# STM32N655 register map
File version: 1.0
CPU: CM55 r0p1, little endian, no MPU, FPU, vendor SysTick, 8 interrupt priority bits
Registers are 32-bit, read-write, reset 0x0 unless marked. A register's access mark holds for its fields unless they carry their own. Offsets are from the block's base; [hi:lo] are bit positions; lines under a group give offsets from that group; {n}, {i} and the like mark numbered series; 'fields as' and 'values as' point back to an identical list.

## DCMIPP (part 2 of 2) — Digital camera interface pixel pipeline
Base 0x48002000
Same registers: DCMIPP_S 0x58002000
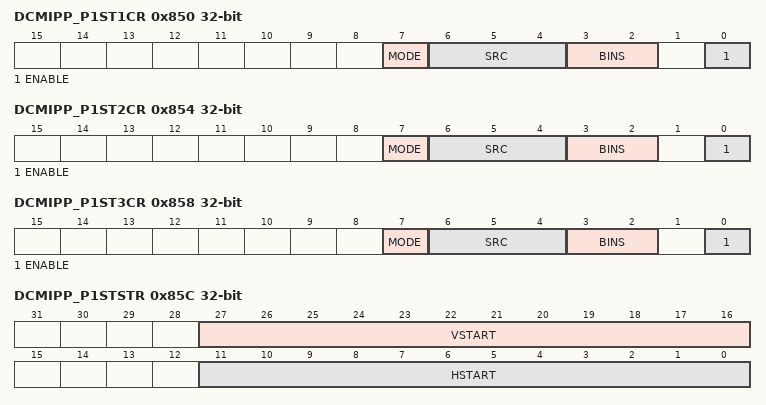
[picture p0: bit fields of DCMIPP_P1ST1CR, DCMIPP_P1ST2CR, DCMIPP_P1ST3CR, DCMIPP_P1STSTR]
0x850 DCMIPP_P1ST1CR — DCMIPP Pipe1 statistics1 control register
  [7] MODE — Statistics mode
    0=Average: accumulates the 8-bit component value of the considered pixel components; 1=Bins: accumulates 256 for each considered pixel component fitting a bin dynamic
  [6:4] SRC — Statistics source
  [3:2] BINS — Current bin definition
    0=All Pixels: Accu is incremented of Component, if 0 less than or equal to Component less than 256; 1=NoExt16: Accu is incremented of Component, if 16 less than or equal to Component less than 240
  [0] ENABLE
    0=Disabled: statistics are not accumulated; 1=Enable: statistics are accumulated
0x854 DCMIPP_P1ST2CR — DCMIPP Pipe1 statistics 2 control register
  [7] MODE — Statistics mode
    values as DCMIPP_P1ST1CR.MODE
  [6:4] SRC — Statistics source
  [3:2] BINS — Bin definition
    0=AllPixels: Accu is incremented of Component, if 0 less than or equal to Component less than 256; 1=NoExt16: Accu is incremented of Component, if 16 less than or equal to Component less than 240
  [0] ENABLE
    0=Disabled: statistics are not accumulated; 1=Enabled: statistics are accumulated
0x858 DCMIPP_P1ST3CR — DCMIPP Pipe1 statistics 3 control register
  fields as DCMIPP_P1ST2CR
0x85C DCMIPP_P1STSTR — DCMIPP Pipe1 statistics window start register
  [27:16] VSTART — Vertical start, from 0 to 4094 pixels high
  [11:0] HSTART — Horizontal start, from 0 to 4094 pixels wide
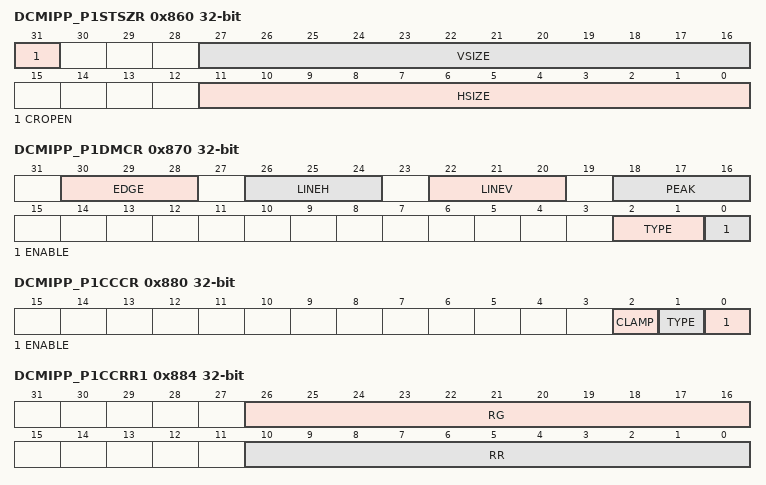
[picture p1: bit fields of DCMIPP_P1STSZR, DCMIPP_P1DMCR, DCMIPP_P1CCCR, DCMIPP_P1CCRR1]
0x860 DCMIPP_P1STSZR — DCMIPP Pipe1 statistics window size register
  [31] CROPEN
    0=Bypass, all pixels are used to compute the statistics; 1=Enable, only the rectangle defined by VSTART, HSTART, VSIZE, HSIZE is used for statistics
  [27:16] VSIZE — Vertical size, from 0 to 4094 pixels high
  [11:0] HSIZE — Horizontal size, from 0 to 4094 pixels wide
0x864 DCMIPP_P1ST1SR ro — DCMIPP Pipe1 statistics 1 status register
  [23:0] ACCU — Accumulation result, divided by 256.
0x868 DCMIPP_P1ST2SR ro — DCMIPP Pipe1 statistics 2 status register
  [23:0] ACCU — accumulation result, divided by 256.
0x86C DCMIPP_P1ST3SR ro — DCMIPP Pipe1 statistics 3 status register
  [23:0] ACCU — accumulation result, divided by 256.
0x870 DCMIPP_P1DMCR — DCMIPP Pipe1 demosaicing configuration register
  [30:28] EDGE — Strength of the edge detection
    0=No edge detection, pure linear interpolation
  [26:24] LINEH — Strength of the horizontal line detection
    0=No horizontal line detection, pure linear interpolation
  [22:20] LINEV — Strength of the vertical line detection
    0=No vertical line detection, pure linear interpolation
  [18:16] PEAK — Strength of the peak detection
    0=No peak detection, pure linear interpolation
  [2:1] TYPE — Raw Bayer type
    0=RGGB; 1=GRBG; 2=GBRG; 3=BGGR
  [0] ENABLE
    0=Bypass; 1=Enable demosaicing
0x880 DCMIPP_P1CCCR — DCMIPP Pipe1 ColorConv configuration register
  [2] CLAMP — Clamp the output samples
    0=Not activated (clamped to [0;255] by default); 1=Activated, depending on TYPE
  [1] TYPE — output samples type used while CLAMP is activated
    0=Clamped to [16;235] for Y and to [16;240] for U and V; 1=Clamped to [16;235] for R, G and B
  [0] ENABLE
    0=ColorConv is bypassed; 1=ColorConv is enabled
0x884 DCMIPP_P1CCRR1 — DCMIPP Pipe1 ColorConv red coefficient register 1
  [26:16] RG — Coefficient row 1 column 2 of the matrix
  [10:0] RR — Coefficient row 1 column 1 of the matrix
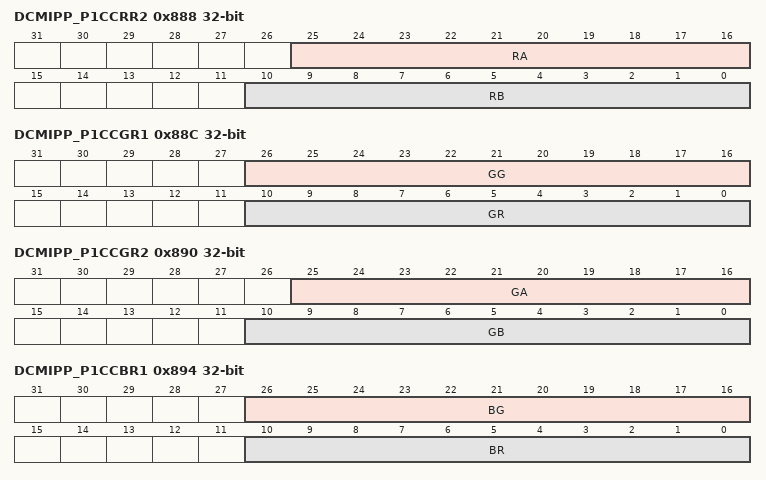
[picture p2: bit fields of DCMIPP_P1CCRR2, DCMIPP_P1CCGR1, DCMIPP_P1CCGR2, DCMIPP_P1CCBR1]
0x888 DCMIPP_P1CCRR2 — DCMIPP Pipe1 ColorConv red coefficient register 2
  [25:16] RA — Coefficient row 1 of the added column (signed integer value)
  [10:0] RB — Coefficient row 1 column 3 of the matrix
0x88C DCMIPP_P1CCGR1 — DCMIPP Pipe1 ColorConv green coefficient register 1
  [26:16] GG — Coefficient row 2 column 2 of the matrix
  [10:0] GR — Coefficient row 2 column 1 of the matrix
0x890 DCMIPP_P1CCGR2 — DCMIPP Pipe1 ColorConv green coefficient register 2
  [25:16] GA — Coefficient row 2 of the added column (signed integer value)
  [10:0] GB — Coefficient row 2 column 3 of the matrix
0x894 DCMIPP_P1CCBR1 — DCMIPP Pipex ColorConv blue coefficient register 1
  [26:16] BG — Coefficient row 3 column 2 of the matrix
  [10:0] BR — Coefficient row 3 column 1 of the matrix
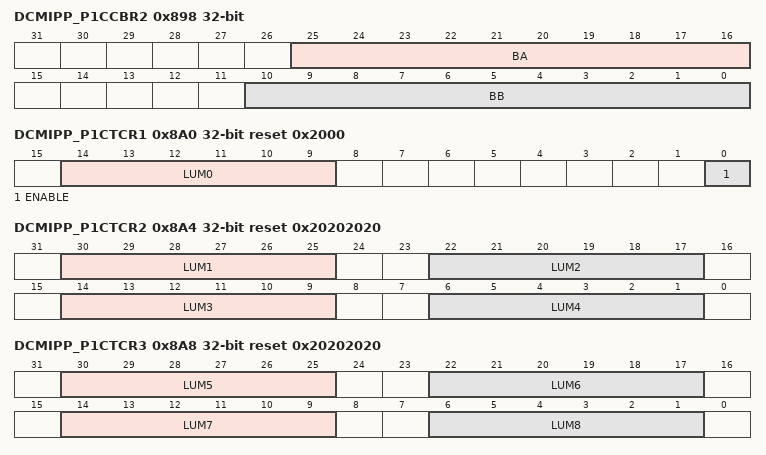
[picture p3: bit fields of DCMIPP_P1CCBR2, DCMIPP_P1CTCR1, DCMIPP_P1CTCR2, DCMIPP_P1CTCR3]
0x898 DCMIPP_P1CCBR2 — DCMIPP Pipe1 ColorConv blue coefficient register 2
  [25:16] BA — Coefficient row 3 of the added column (signed integer value)
  [10:0] BB — Coefficient row 3 column 3 of the matrix
0x8A0 DCMIPP_P1CTCR1 reset 0x2000 — DCMIPP Pipe1 contrast control register 1
  [14:9] LUM0 — Luminance increase for input luminance of 0 (increase is idle with LUMx = 16)
  [0] ENABLE
    0=Bypass, pixels are forwarded idle; 1=Enable, contrast enhancement is applied on pixels
0x8A4 DCMIPP_P1CTCR2 reset 0x20202020 — DCMIPP Pipe1 contrast control register 2
  [38-8n:33-8n] LUM{n} (n=1..4) — Luminance increase for input luminance of {32n} (increase is idle with LUMx = 16)
0x8A8 DCMIPP_P1CTCR3 reset 0x20202020 — DCMIPP Pipe1 contrast control register 3
  [70-8n:65-8n] LUM{n} (n=5..8) — Luminance increase for input luminance of {32n} (increase is idle with LUMx = 16)
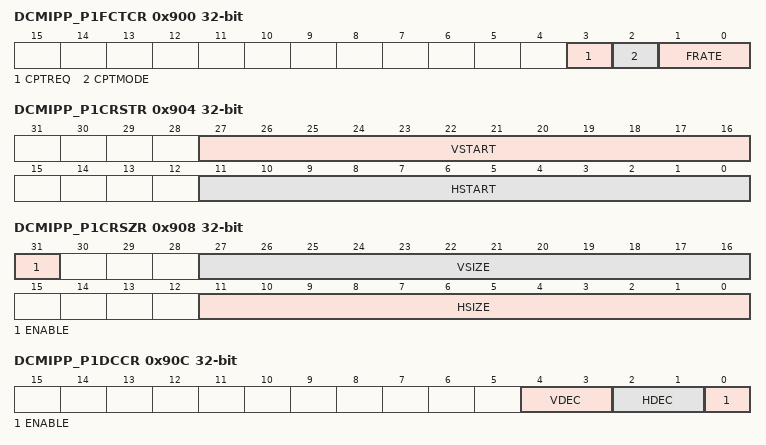
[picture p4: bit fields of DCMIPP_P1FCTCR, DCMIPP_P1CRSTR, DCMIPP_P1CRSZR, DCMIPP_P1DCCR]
0x900 DCMIPP_P1FCTCR — DCMIPP Pipex flow control configuration register
  [3] CPTREQ — Capture requested
    0=Capture not requested for next frame; 1=Capture requested for next frame
  [2] CPTMODE — Capture mode
    0=Continuous grab mode. The received data are transferred into the destination memory through the AXI master.; 1=Snapshot mode (single frame). Once activated, the interface waits for the start of frame and then transfers a single frame through the AXI master. At the end of the frame, the CPTACT bit is automatically reset.
  [1:0] FRATE — Frame capture rate control
    0=All frames are captured; 1=One out of two frames captured (50% bandwidth reduction); 2=One out of four frames captured (75% bandwidth reduction); 3=One out of eight frames captured (87% bandwidth reduction)
0x904 DCMIPP_P1CRSTR — DCMIPP Pipex crop window start register
  fields as DCMIPP_P1STSTR
0x908 DCMIPP_P1CRSZR — DCMIPP Pipex crop window size register
  [31] ENABLE
    0=Bypass, all pixels are transmitted through (no need to set any start and size values); 1=Enable, only the rectangle defined by VSIZE, HSIZE, VSTART, HSTART is transmitted
  [27:16] VSIZE — Vertical size, from 0 to 4094 pixels high. If the value is maintained at 0 when enabling the crop thanks to the ENABLE bit, the value is forced internally at 0xFFE, which is the maximum value.
  [11:0] HSIZE — Horizontal size, from 0 to 4094 pixels wide. If the value is maintained at 0 when enabling the crop by means of the ENABLE bit, the value is forced internally at 0xFFE, which is the maximum value.
0x90C DCMIPP_P1DCCR — DCMIPP Pipex decimation register
  [4:3] VDEC — Vertical decimation ratio
    0=All pixels are transmitted, no vertical decimation; 1=One line out of two transmitted
  [2:1] HDEC — Horizontal decimation ratio
    0=All pixels are transmitted, no horizontal decimation; 1=One line out of two transmitted
  [0] ENABLE
    0=Bypass: decimation is not active, all pixels are transmitted; 1=Enable: one pixel every 1, 2, 4 or 8, in H and V is transmitted, following HDEC and VDEC
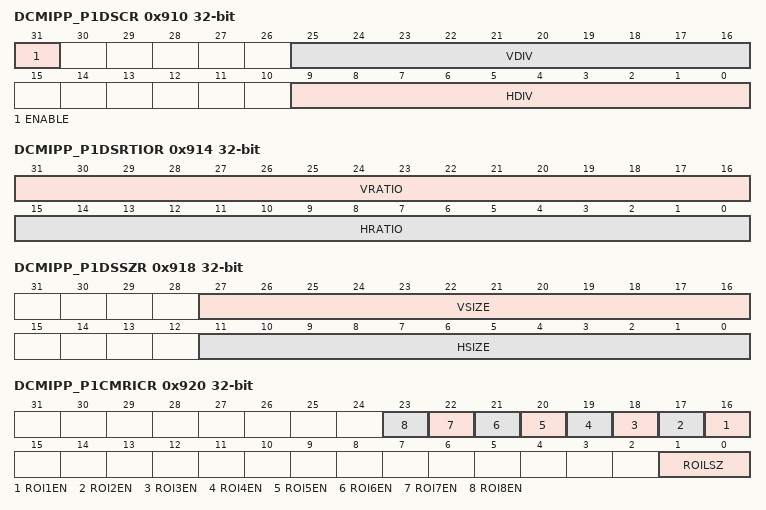
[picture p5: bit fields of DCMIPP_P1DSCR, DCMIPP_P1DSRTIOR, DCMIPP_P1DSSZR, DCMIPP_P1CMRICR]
0x910 DCMIPP_P1DSCR — DCMIPP Pipex downsize configuration register
  [31] ENABLE
    0=Down scaler is bypassed; 1=Down scaler is enabled
  [25:16] VDIV — Vertical division factor, from 128 (8x) to 1023 (1x)
  [9:0] HDIV — Horizontal division factor, from 128 (8x) to 1023 (1x)
0x914 DCMIPP_P1DSRTIOR — DCMIPP Pipex downsize ratio register
  [31:16] VRATIO — Vertical ratio, from 8192 (1x) to 65535 (8x)
  [15:0] HRATIO — Horizontal ratio, from 8192 (1x) to 65535 (8x)
0x918 DCMIPP_P1DSSZR — DCMIPP Pipex downsize destination size register
  [27:16] VSIZE — Vertical size, from 0 to 4094 pixels high
  [11:0] HSIZE — Horizontal size, from 0 to 4094 pixels wide
0x920 DCMIPP_P1CMRICR — DCMIPP Pipex common ROI configuration register
  [n+15] ROI{n}EN (n=1..8) — Region of interest {n} enable
    0=Disable ROI; 1=Enable ROI
  [1:0] ROILSZ — Region of interest line size width
    0=Line width 1 pixel; 1=Line width 2 pixels; 2=Line width 4 pixels; 3=Line width 8 pixels
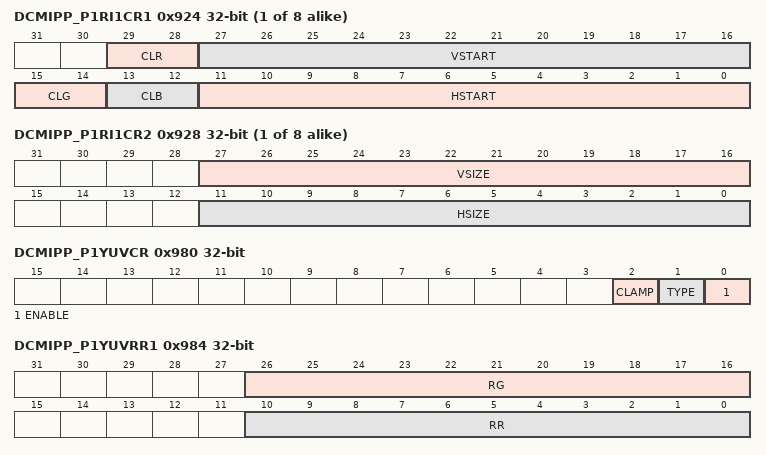
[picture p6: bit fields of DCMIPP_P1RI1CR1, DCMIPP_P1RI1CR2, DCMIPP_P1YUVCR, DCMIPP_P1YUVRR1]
{0x91C+8i} DCMIPP_P1RI{i}CR1 (i=1..8) — DCMIPP Pipe1 ROI{i} configuration register 1
  [29:28] CLR — Color line red
  [27:16] VSTART — Vertical start, from 0 to 4094 pixels high
  [15:14] CLG — Color line green
  [13:12] CLB — Color line blue
  [11:0] HSTART — Horizontal start, from 0 to 4094 pixels wide
{0x920+8i} DCMIPP_P1RI{i}CR2 (i=1..8) — DCMIPP Pipe1 ROI{i} configuration register 2
  fields as DCMIPP_P1DSSZR
0x970 DCMIPP_P1GMCR — DCMIPP Pipex gamma configuration register
  [0] ENABLE
    0=Gamma is bypassed; 1=Gamma is enabled
0x980 DCMIPP_P1YUVCR — DCMIPP Pipe1 YUVConv configuration register
  [2] CLAMP — Clamp the output samples
    values as DCMIPP_P1CCCR.CLAMP
  [1] TYPE — Output samples type used while CLAMP is activated
    values as DCMIPP_P1CCCR.TYPE
  [0] ENABLE
    0=ColorConv is bypassed; 1=ColorConv is enabled
0x984 DCMIPP_P1YUVRR1 — DCMIPP Pipe1 YUVConv red coefficient register 1
  fields as DCMIPP_P1CCRR1
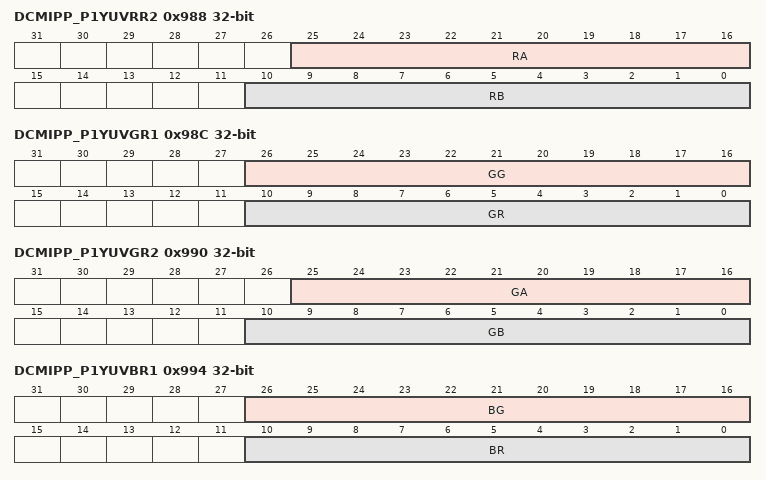
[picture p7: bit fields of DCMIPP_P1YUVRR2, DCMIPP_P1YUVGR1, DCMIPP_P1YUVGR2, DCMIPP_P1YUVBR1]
0x988 DCMIPP_P1YUVRR2 — DCMIPP Pipe1 YUVConv red coefficient register 2
  fields as DCMIPP_P1CCRR2
0x98C DCMIPP_P1YUVGR1 — DCMIPP Pipe1 YUVConv green coefficient register 1
  fields as DCMIPP_P1CCGR1
0x990 DCMIPP_P1YUVGR2 — DCMIPP Pipe1 YUVConv green coefficient register 2
  fields as DCMIPP_P1CCGR2
0x994 DCMIPP_P1YUVBR1 — DCMIPP Pipe1 YUVConv blue coefficient register 1
  fields as DCMIPP_P1CCBR1
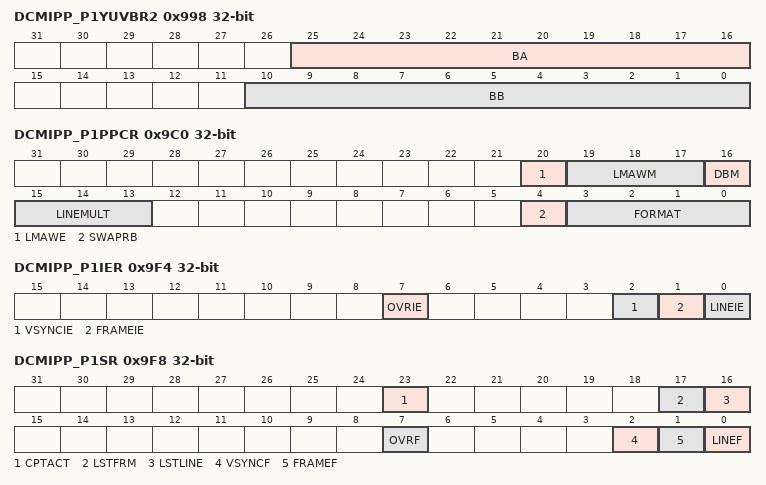
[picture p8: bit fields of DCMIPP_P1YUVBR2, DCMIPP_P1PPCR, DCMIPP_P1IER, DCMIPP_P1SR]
0x998 DCMIPP_P1YUVBR2 — DCMIPP Pipe1 YUV blue coefficient register 2
  fields as DCMIPP_P1CCBR2
0x9C0 DCMIPP_P1PPCR — DCMIPP Pipe1 pixel packer configuration register
  [20] LMAWE — Line multi address wrapping enable bit.
    0=Line multi address wrapping disabled; 1=Line multi address wrapping enabled
  [19:17] LMAWM — Line multi address wrapping modulo.
    0=Wraps address after every line; 1=Wraps address after two lines; 2=Wraps address after four lines; 3=Wraps address after eight lines; 4=Wraps address after sixteen lines; 5=Wraps address after 32 lines; 6=Wraps address after 64 lines; 7=Wraps address after 128 lines
  [16] DBM — Double buffer mode
    0=No double buffer mode activated. Pipe1 always drains out the pixels to memory address set by DCMIPP_P1PPM0AR1, and DCMIPP_P1PPM1AR1 as well as DCMIPP_P1PPM2AR1 in case of semi-planar or multi-planar buffer configuration; 1=Double buffer mode activated. Output pixels address location switches from DCMIPP_P1PPM0AR1 to DCMIPP_P1PPM0AR2 alternatively on each frame. For the semi- and multi-planar operations, the output pixels switches from/to DCMIPP_P1PPM1AR1 to/from DCMIPP_P1PPM1AR2. Memory buffer switches from/to DCMIPP_P1PPM2AR1 to/from DCMIPP_P1PPM2AR2 for multi-planar operations.
  [15:13] LINEMULT — Amount of capture completed lines for LINE Event and Interrupt
    0=Event after one line; 1=Event after two lines; 2=Event after four lines; 3=Event after eight lines; 4=Event after sixteen lines; 5=Event after 32 lines; 6=Event after 64 lines; 7=Event after 128 lines
  [4] SWAPRB — Swaps R-vs-B components if RGB, and U-vs-V components if YUV
    0=No swap of R-vs-B (U-vs-V); 1=Swap active
  [3:0] FORMAT — Memory format
    0=RGB888 or YUV444 1-buffer; 1=RGB565 1-buffer; 2=ARGB8888 (with A = 0xFF); 3=RGBA8888 (with A = 0xFF); 4=monochrome Y8 or G8 1-buffer; 5=YUV444 1-buffer (32 bpp, FOURCC = AYUV, with A = 0xFF); 6=YUV422 1-buffer (16 bpp, FOURCC = YUYV); 7=YUV422 2-buffer (16 bpp, FOURCC = none); 8=YUV420 2-buffer (12 bpp, FOURCC = NV21), NV12 available with SWAPRB = 1; 9=YUV420 3-buffer (12 bpp, FOURCC = YV12); 10=YUV422 1-buffer (16 bpp, FOURCC = UYVY)
0x9CC DCMIPP_P1PPM0PR — DCMIPP Pipex pixel packer Memory0 pitch register
  [14:0] PITCH — Number of bytes between the address of two consecutive lines.
{0x9D0+0x10*i} DCMIPP_P1STM{i}AR ro (i=0..2) — DCMIPP Pipex status Memory{i} address register
  [31:0] M{i}A — Memory{i} address
0x9D4 DCMIPP_P1PPM1AR1 — DCMIPP Pipex pixel packer Memory1 address register 1
  [31:0] M1A — Memory1 address
0x9D8 DCMIPP_P1PPM1AR2 — DCMIPP Pipex pixel packer Memory1 address register 2
  [31:0] M1A — Memory1 address
0x9DC DCMIPP_P1PPM1PR — DCMIPP Pipex pixel packer Memory1 pitch register
  fields as DCMIPP_P1PPM0PR
0x9E4 DCMIPP_P1PPM2AR1 — DCMIPP Pipex pixel packer memory2 address register 1
  [31:0] M2A — Memory 2 address
0x9E8 DCMIPP_P1PPM2AR2 — DCMIPP Pipex pixel packer memory2 address register 2
  [31:0] M2A — Memory 2 address
0x9F4 DCMIPP_P1IER — DCMIPP Pipe1 interrupt enable register
  [7] OVRIE — Overrun interrupt enable
    0=No interrupt generation; 1=An interrupt is generated if the AXI master is unable to transfer the last data before new data (32-bit) are received
  [2] VSYNCIE — VSYNC interrupt enable
    0=No interrupt generation; 1=An interrupt is generated on each VSYNC (captured or not)
  [1] FRAMEIE — Frame capture completed interrupt enable
    0=No interrupt generation; 1=An interrupt is generated after the full capture of a cropped frame
  [0] LINEIE — Multi-line capture completed interrupt enable
    0=No interrupt generation when the line is received; 1=An interrupt is generated after the full capture of a group of lines (or last line reached)
0x9F8 DCMIPP_P1SR ro — DCMIPP Pipe1 status register
  [23] CPTACT — Capture immediate status
    0=Capture currently inactive; 1=Capture currently active
  [17] LSTFRM — Last frame LSB bit, sampled at frame capture complete event. The information is extracted from the frame data number, which can be delivered by the camera through the CSI2 interface.
  [16] LSTLINE — Last line LSB bit, sampled at frame capture complete event.
  [7] OVRF — Overrun raw interrupt status
    0=No data buffer overrun occurred; 1=A data buffer overrun occurred and this frame data are corrupted
  [2] VSYNCF — VSYNC raw interrupt status
  [1] FRAMEF — Frame capture completed raw interrupt status
    0=No capture or ongoing capture; 1=All data of a frame have been captured
  [0] LINEF — Multi-line capture completed raw interrupt status
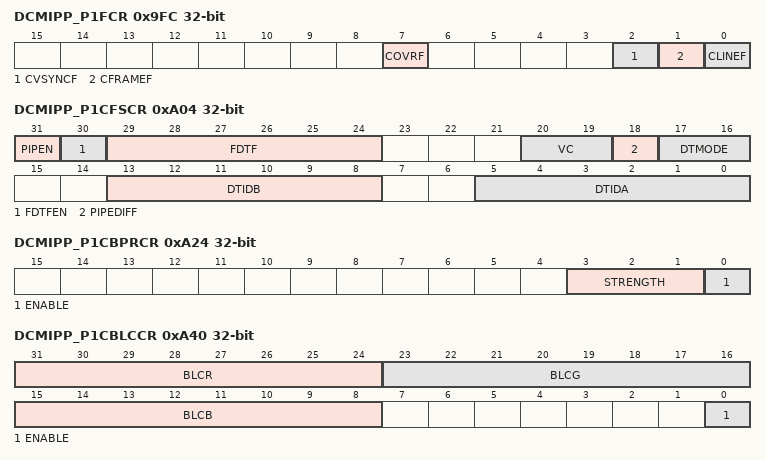
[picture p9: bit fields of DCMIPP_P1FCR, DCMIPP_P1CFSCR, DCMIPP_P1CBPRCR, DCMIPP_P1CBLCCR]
0x9FC DCMIPP_P1FCR wo — DCMIPP Pipe1 interrupt clear register
  [7] COVRF — Overrun interrupt status clear
  [2] CVSYNCF — Vertical synchronization interrupt status clear
  [1] CFRAMEF — Frame capture complete interrupt status clear
  [0] CLINEF — Multi-line capture complete interrupt status clear
0xA04 DCMIPP_P1CFSCR ro — DCMIPP Pipe1 current flow selection configuration register
  [31] PIPEN — Current activation of PipeN
    0=Pipe disabled; 1=Pipe enabled, can start capturing with CPTMODE, CPTREQ, CPTACK
  [30] FDTFEN — Current force data type format enable
    0=Disable force data type format. The data type format used by the pipe is the one defined into DTIDx; 1=Enable force data type format. When the data type DTIDx is detected by the pipe, the real pixel format considering by the pipe is the one set into the FDTF[5:0] bit field instead of the physical one received by the CSI2 host. It allows to handle, for instance, 3D sensors camera with user data type in bottom-up approach, and to explicitly define the pixel format to be handled by the pipe.
  [29:24] FDTF — Current force data type format
  [20:19] VC — Current flow selection mode
  [18] PIPEDIFF — Current differentiates Pipe2 vs. Pipe1
    0=Pipe2 gets Pipe1 pixels after their processing in shared Gamma, StatRemoval, Demosaicing. Pipe2 shares the same VC DTID of Pipe1 when a CSI2 camera sensor is plugged.; 1=Pipe1 gets pixels from only VC/DTID configured in pipe1, processed by all including Gamma, StatRemoval, Demosaicing. Pipe2 gets pixels from only VC/DTID configured in Pipe2, processed from Crop only (Gamma common with Pipe1, no StatRem, no demosaicing)
  [17:16] DTMODE — Flow selection mode
    0=Only flow DTID A from the selected virtual channel is forwarded in the pipe; 1=Flows DTIDA and DTIDB from the selected virtual channel are forwarded in the pipe. This combination is valid only if the FDTFEN bit is set.
  [13:8] DTIDB — Current data type ID B
  [5:0] DTIDA — Current data type ID A
0xA24 DCMIPP_P1CBPRCR ro — DCMIPP Pipe1 current bad pixel removal register
  [3:1] STRENGTH — Current strength (aggressiveness) of the bad pixel detection:
    0=the filter is fairly tolerant: only a few pixels are declared bad, due to their high noise
  [0] ENABLE — Current status of enable bit
    0=Bypass: bad pixel removal is not active, all pixels are transmitted through; 1=Enable: if bad pixel are detected, they are replaced by corrected pixels
0xA40 DCMIPP_P1CBLCCR ro — DCMIPP Pipe1 current black level calibration control register
  [31:24] BLCR — Current black level calibration - Red
  [23:16] BLCG — Current black level calibration - Green
  [15:8] BLCB — Current black level calibration - Blue
  [0] ENABLE — For current black level calibration
    0=Bypass: black level calibration is not active, all pixels are transmitted non-modified; 1=Enable: the BLCR, G, B are subtracted
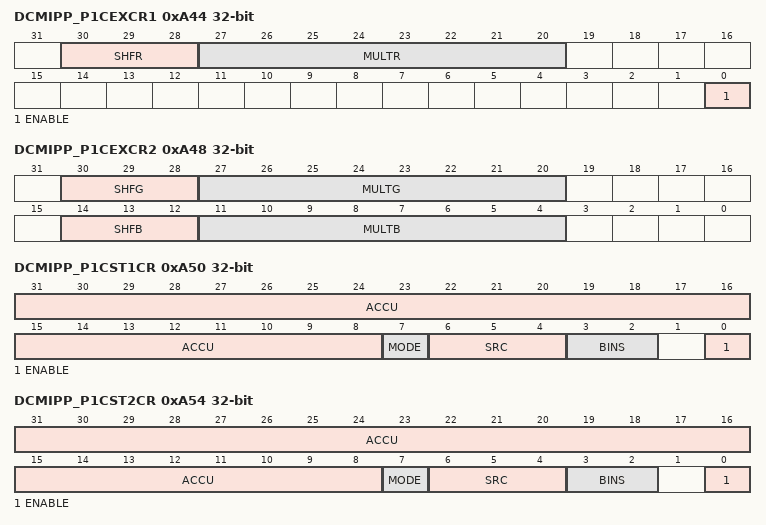
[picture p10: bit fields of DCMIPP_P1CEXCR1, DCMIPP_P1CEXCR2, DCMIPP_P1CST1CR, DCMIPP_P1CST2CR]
0xA44 DCMIPP_P1CEXCR1 ro — DCMIPP Pipe1 current exposure control register 1
  [30:28] SHFR — Current exposure shift - Red
  [27:20] MULTR — Current exposure multiplier - Red
  [0] ENABLE — for exposure control (multiplication and shift)
    0=Bypass: exposure multiplier and shift are not applied; 1=Enable: the exposure multiplication and shift is applied
0xA48 DCMIPP_P1CEXCR2 ro — DCMIPP Pipe1 current exposure control register 2
  [30:28] SHFG — Current exposure shift - Green
  [27:20] MULTG — Current exposure multiplier - Green
  [14:12] SHFB — Current exposure shift - Blue
  [11:4] MULTB — Current exposure multiplier - Blue
0xA50 DCMIPP_P1CST1CR ro — DCMIPP Pipe1 current statistics 1 control register
  [31:8] ACCU — Current accumulation result, divided by 256.
  [7] MODE — Current statistics mode
    values as DCMIPP_P1ST1CR.MODE
  [6:4] SRC — Current source of statistics
  [3:2] BINS — Current bin definition
    values as DCMIPP_P1ST2CR.BINS
  [0] ENABLE — Current enable bit value
    values as DCMIPP_P1ST1CR.ENABLE
0xA54 DCMIPP_P1CST2CR ro — DCMIPP Pipe1 current statistics 2 control register
  [31:8] ACCU — Accumulation result, divided by 256.
  [7] MODE — Statistics mode
    values as DCMIPP_P1ST1CR.MODE
  [6:4] SRC — Statistics source
  [3:2] BINS — Bin definition
    values as DCMIPP_P1ST2CR.BINS
  [0] ENABLE
    values as DCMIPP_P1ST1CR.ENABLE
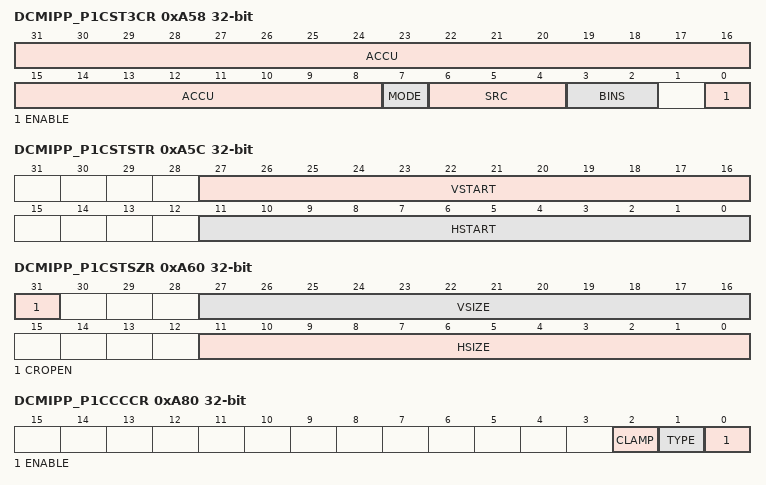
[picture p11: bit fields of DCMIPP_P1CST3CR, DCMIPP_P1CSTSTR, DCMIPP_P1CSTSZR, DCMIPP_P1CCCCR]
0xA58 DCMIPP_P1CST3CR ro — DCMIPP Pipe1 current statistics 3 control register
  [31:8] ACCU — Accumulation result, divided by 256.
  [7] MODE — Statistics mode
    values as DCMIPP_P1ST1CR.MODE
  [6:4] SRC — Statistics source
  [3:2] BINS — Current bin definition
    values as DCMIPP_P1ST2CR.BINS
  [0] ENABLE
    values as DCMIPP_P1ST1CR.ENABLE
0xA5C DCMIPP_P1CSTSTR ro — DCMIPP Pipe1 current statistics window start register
  [27:16] VSTART — Current vertical start, from 0 to 4094 pixels high
  [11:0] HSTART — Current horizontal start, from 0 to 4094 pixels wide
0xA60 DCMIPP_P1CSTSZR ro — DCMIPP Pipe1 current statistics window size register
  [31] CROPEN — Current CROPEN bit value
    0=Bypass, all pixels are used to compute the statistics; 1=Enable, only the rectangle defined by VSTART, HSTART, VSIZE, HSIZE, are used for statistics
  [27:16] VSIZE — Current vertical size, from 0 to 4094 pixels high
  [11:0] HSIZE — Current horizontal size, from 0 to 4094 pixels wide
0xA80 DCMIPP_P1CCCCR ro — DCMIPP Pipe1 current ColorConv configuration register
  [2] CLAMP — Clamp the output samples
    values as DCMIPP_P1CCCR.CLAMP
  [1] TYPE — Output samples type used while CLAMP is activated
    0=clamped to [16;235] for Y and to [16;240] for U and V; 1=clamped to [16;235] for R, G and B
  [0] ENABLE — Current value applied
    0=ColorConv is bypassed; 1=ColorConv is enabled
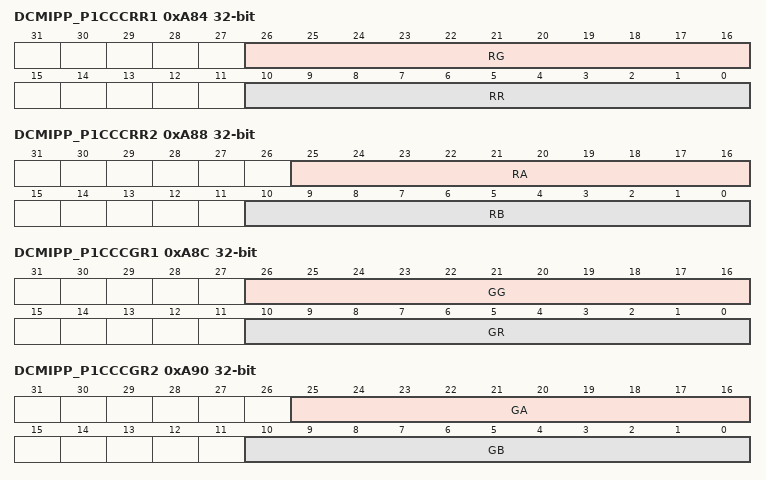
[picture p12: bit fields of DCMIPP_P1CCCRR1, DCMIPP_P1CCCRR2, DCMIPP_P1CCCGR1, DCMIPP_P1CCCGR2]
0xA84 DCMIPP_P1CCCRR1 ro — DCMIPP Pipe1 current ColorConv red coefficient register 1
  [26:16] RG — Current coefficient row 1 column 2 of the matrix
  [10:0] RR — Current coefficient row 1 column 1 of the matrix
0xA88 DCMIPP_P1CCCRR2 ro — DCMIPP Pipe1 current ColorConv red coefficient register 2
  [25:16] RA — Current coefficient row 1 of the added column (signed integer value)
  [10:0] RB — Current coefficient row 1 column 3 of the matrix
0xA8C DCMIPP_P1CCCGR1 ro — DCMIPP Pipe1 current ColorConv green coefficient register 1
  [26:16] GG — Current coefficient row 2 column 2 of the matrix
  [10:0] GR — Current coefficient row 2 column 1 of the matrix
0xA90 DCMIPP_P1CCCGR2 ro — DCMIPP Pipe1 current ColorConv green coefficient register 2
  [25:16] GA — Current coefficient row 2 of the added column (signed integer value)
  [10:0] GB — Current coefficient row 2 column 3 of the matrix
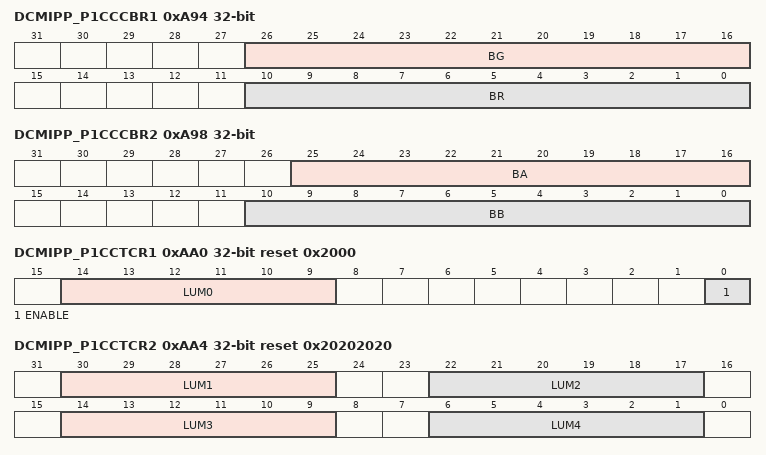
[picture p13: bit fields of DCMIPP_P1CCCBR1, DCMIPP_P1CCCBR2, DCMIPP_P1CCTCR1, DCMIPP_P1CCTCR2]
0xA94 DCMIPP_P1CCCBR1 ro — DCMIPP Pipex current ColorConv blue coefficient register 1
  [26:16] BG — Current coefficient row 3 column 2 of the matrix
  [10:0] BR — Current coefficient row 3 column 1 of the matrix
0xA98 DCMIPP_P1CCCBR2 ro — DCMIPP Pipe1 current ColorConv blue coefficient register 2
  [25:16] BA — Current coefficient row 3 of the added column (signed integer value)
  [10:0] BB — Current coefficient row 3 column 3 of the matrix
0xAA0 DCMIPP_P1CCTCR1 ro reset 0x2000 — DCMIPP Pipe1 current contrast control register 1
  [14:9] LUM0 — Current luminance increase for input luminance of 0 (increase is idle with LUMx = 16)
  [0] ENABLE — Current ENABLE bit value
    values as DCMIPP_P1CTCR1.ENABLE
0xAA4 DCMIPP_P1CCTCR2 ro reset 0x20202020 — DCMIPP Pipe1 current contrast control register 2
  [38-8n:33-8n] LUM{n} (n=1..4) — Current luminance increase for input luminance of {32n} (increase is idle with LUMx = 16)
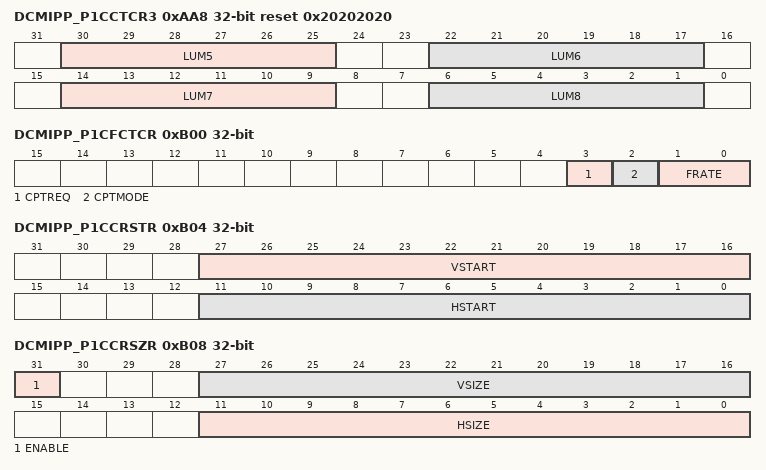
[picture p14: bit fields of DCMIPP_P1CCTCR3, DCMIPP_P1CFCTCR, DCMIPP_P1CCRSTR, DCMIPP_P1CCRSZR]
0xAA8 DCMIPP_P1CCTCR3 ro reset 0x20202020 — DCMIPP Pipe1 current contrast control register 3
  fields as DCMIPP_P1CTCR3
0xB00 DCMIPP_P1CFCTCR ro — DCMIPP Pipex current flow control configuration register
  [3] CPTREQ — Capture requested
    values as DCMIPP_P1FCTCR.CPTREQ
  [2] CPTMODE — Capture mode
    0=Continuous grab mode - Received data are transferred into the destination memory through the AXI master; 1=Snapshot mode (single frame) - Once activated, the interface waits for the start of frame and then transfers a single frame through the AXI master. At the end of the frame, the CPTACT bit is automatically reset.
  [1:0] FRATE — Frame capture rate control
    values as DCMIPP_P1FCTCR.FRATE
0xB04 DCMIPP_P1CCRSTR ro — DCMIPP Pipex current crop window start register
  fields as DCMIPP_P1CSTSTR
0xB08 DCMIPP_P1CCRSZR ro — DCMIPP Pipex current crop window size register
  [31] ENABLE — Current ENABLE bit value.
    values as DCMIPP_P1CRSZR.ENABLE
  [27:16] VSIZE — Current vertical size, from 0 to 4094 pixels high
  [11:0] HSIZE — Current horizontal size, from 0 to 4094 pixels wide
0xB0C DCMIPP_P1CDCCR — DCMIPP Pipex current decimation register
  fields as DCMIPP_P1DCCR
0xB10 DCMIPP_P1CDSCR ro — DCMIPP Pipex current downsize configuration register
  [31] ENABLE — Current value of bit ENABLE
    0=Down scaler is bypassed; 1=Down scaler is enabled
  [25:16] VDIV — Current vertical division factor, from 128 (8x) to 1023 (1x)
  [9:0] HDIV — Current horizontal division factor, from 128 (8x) to 1023 (1x)
0xB14 DCMIPP_P1CDSRTIOR ro — DCMIPP Pipex current downsize ratio register
  [31:16] VRATIO — Current vertical ratio, from 8192 (1x) to 65535 (8x)
  [15:0] HRATIO — Current horizontal ratio, from 8192 (1x) to 65535 (8x)
0xB18 DCMIPP_P1CDSSZR ro — DCMIPP Pipex current downsize destination size register
  [27:16] VSIZE — Current vertical size, from 0 to 4094 pixels high
  [11:0] HSIZE — Current horizontal size, from 0 to 4094 pixels wide
0xB20 DCMIPP_P1CCMRICR ro — DCMIPP Pipex current common ROI configuration register
  [n+15] ROI{n}EN (n=1..8) — Current region of interest {n} enable
    0=Disable ROI; 1=Enable ROI
  [1:0] ROILSZ — Current region of interest line size width
    values as DCMIPP_P1CMRICR.ROILSZ
{0xB1C+8i} DCMIPP_P1CRI{i}CR1 ro (i=1..8) — DCMIPP Pipe1 current ROI{i} configuration register 1
  [29:28] CLR — Current color line red
  [27:16] VSTART — Current vertical start, from 0 to 4094 pixels high
  [15:14] CLG — Current color line green
  [13:12] CLB — Current color line blue
  [11:0] HSTART — Current horizontal start, from 0 to 4094 pixels wide
{0xB20+8i} DCMIPP_P1CRI{i}CR2 ro (i=1..8) — DCMIPP Pipe1 current ROI{i} configuration register 2
  fields as DCMIPP_P1CDSSZR
0xBC0 DCMIPP_P1CPPCR ro — DCMIPP Pipe1 current pixel packer configuration register
  [20] LMAWE — Line multi address wrapping enable bit
    values as DCMIPP_P1PPCR.LMAWE
  [19:17] LMAWM — Line multi address wrapping modulo
    values as DCMIPP_P1PPCR.LMAWM
  [16] DBM — Double buffer mode
    values as DCMIPP_P1PPCR.DBM
  [15:13] LINEMULT — Amount of capture completed lines for LINE Event and Interrupt
    values as DCMIPP_P1PPCR.LINEMULT
  [4] SWAPRB — Swaps R-vs-B components if RGB, and U-vs-V components if YUV
    0=No swap of R-vs-B (U-vs-V); 1=Swap active
  [3:0] FORMAT — Memory format
    values as DCMIPP_P1PPCR.FORMAT
0xBCC DCMIPP_P1CPPM0PR ro — DCMIPP Pipex current pixel packer Memory0 pitch register
  [14:0] PITCH — Current number of bytes between the address of two consecutive lines.
0xBD4 DCMIPP_P1CPPM1AR1 ro — DCMIPP Pipex current pixel packer Memory1 address register 1
  [31:0] M1A — Memory1 address
0xBD8 DCMIPP_P1CPPM1AR2 ro — DCMIPP Pipex current pixel packer Memory1 address register 2
  [31:0] M1A — Memory1 address
0xBDC DCMIPP_P1CPPM1PR ro — DCMIPP Pipex current pixel packer Memory1 pitch register
  [14:0] PITCH — Current number of bytes between the address of two consecutive lines
0xBE4 DCMIPP_P1CPPM2AR1 ro — DCMIPP Pipex current pixel packer Memory2 address register 1
  [31:0] M2A — Memory 2 address
0xBE8 DCMIPP_P1CPPM2AR2 ro — DCMIPP Pipex current pixel packer Memory2 address register 1
  [31:0] M2A — Memory 2 address
0xC04 DCMIPP_P2FSCR — DCMIPP Pipe2 flow selection configuration register
  [31] PIPEN — Activation of PipeN
    0=PipeN disabled; 1=PipeN enabled, can start capturing with CPTMODE, CPTREQ, CPTACK
  [30] FDTFEN — Force data type format enable
    0=Disable force data type format. The data type format used by the pipe is the one defined into DTIDx; 1=Enable force data type format. When the data type DTIDA is detected by the pipe, the real pixel format considered by the pipe is the one set into the FDTF[5:0] bit field instead of the physical one received by the CSI2 host.
  [29:24] FDTF — Force data type format
  [20:19] VC — Flow selection mode
  [5:0] DTIDA — Data type ID
0xD00 DCMIPP_P2FCTCR — DCMIPP Pipex flow control configuration register
  fields as DCMIPP_P1FCTCR
0xD04 DCMIPP_P2CRSTR — DCMIPP Pipex crop window start register
  fields as DCMIPP_P1STSTR
0xD08 DCMIPP_P2CRSZR — DCMIPP Pipex crop window size register
  fields as DCMIPP_P1CRSZR
0xD0C DCMIPP_P2DCCR — DCMIPP Pipex decimation register
  fields as DCMIPP_P1DCCR
0xD10 DCMIPP_P2DSCR — DCMIPP Pipex downsize configuration register
  fields as DCMIPP_P1DSCR
0xD14 DCMIPP_P2DSRTIOR — DCMIPP Pipex downsize ratio register
  fields as DCMIPP_P1DSRTIOR
0xD18 DCMIPP_P2DSSZR — DCMIPP Pipex downsize destination size register
  fields as DCMIPP_P1DSSZR
0xD20 DCMIPP_P2CMRICR — DCMIPP Pipex common ROI configuration register
  fields as DCMIPP_P1CMRICR
{0xD1C+8i} DCMIPP_P2RI{i}CR1 (i=1..8) — DCMIPP Pipe2 ROI{i} configuration register 1
  fields as DCMIPP_P1RI1CR1
{0xD20+8i} DCMIPP_P2RI{i}CR2 (i=1..8) — DCMIPP Pipe2 ROI{i} configuration register 2
  fields as DCMIPP_P1DSSZR
0xD70 DCMIPP_P2GMCR — DCMIPP Pipex gamma configuration register
  [0] ENABLE
    0=Gamma is bypassed; 1=Gamma is enabled
0xDC0 DCMIPP_P2PPCR — DCMIPP Pipe2 pixel packer configuration register
  [20] LMAWE — Line multi address wrapping enable bit
    values as DCMIPP_P1PPCR.LMAWE
  [19:17] LMAWM — Line multi address wrapping modulo
    values as DCMIPP_P1PPCR.LMAWM
  [16] DBM — Double buffer mode
    0=No double buffer mode activated. Pipe2 is always dump to memory address set by DCMIPP_P2PPM0AR1; 1=Double buffer mode activated. Dump address location switches from DCMIPP_P2PPM0AR1 register to DCMIPP_P2PPM0AR2 register alternatively on each frame
  [15:13] LINEMULT — Amount of capture completed lines for LINE event and interrupt
    0=Event after every line; 1=Event after two lines; 2=Event after four lines; 3=Event after eight lines; 4=Event after sixteen lines; 5=Event after 32 lines; 6=Event after 64 lines; 7=Event after 128 lines
  [4] SWAPRB — Swaps R-vs-B components if RGB, and if YUV, swaps U-vs-V components
    0=No swap of R-vs-B (U-vs-V); 1=Swap active
  [3:0] FORMAT — Memory format (only coplanar formats are supported in Pipe2)
    0=RG/B888 or YUV444 1-buffer; 1=RGB565 1-buffer; 2=ARGB8888; 3=RGBA8888; 4=monochrome Y8 or G8 1-buffer; 5=YUV444 1-buffer (FOURCC = AYUV); 6=YUV422 1-buffer (FOURCC = YUYV)
0xDCC DCMIPP_P2PPM0PR — DCMIPP Pipex pixel packer Memory0 pitch register
  fields as DCMIPP_P1PPM0PR
0xDD0 DCMIPP_P2STM0AR ro — DCMIPP Pipex status Memory0 address register
  [31:0] M0A — Memory0 address
0xDF4 DCMIPP_P2IER — DCMIPP Pipe2 interrupt enable register
  fields as DCMIPP_P1IER
0xDF8 DCMIPP_P2SR ro — DCMIPP Pipe2 status register
  [23] CPTACT — Capture immediate status
    0=Capture currently inactive; 1=Capture currently active
  [17] LSTFRM — Last frame LSB bit, sampled at frame capture complete event. The information is extracted from the frame data number which can be delivered by the camera through the CSI2 interface.
  [16] LSTLINE — Last line LSB bit, sampled at frame capture complete event.
  [7] OVRF — Overrun raw interrupt status
    0=No data buffer overrun occurred; 1=A data buffer overrun occurred and data of this frame are corrupted
  [2] VSYNCF — VSYNC raw interrupt status
  [1] FRAMEF — Frame capture completed raw interrupt status
    values as DCMIPP_P1SR.FRAMEF
  [0] LINEF — Multi-line capture completed raw interrupt status
0xDFC DCMIPP_P2FCR wo — DCMIPP Pipe2 interrupt clear register
  fields as DCMIPP_P1FCR
0xE04 DCMIPP_P2CFSCR ro — DCMIPP Pipe2 current flow selection configuration register
  [31] PIPEN — Current activation of PipeN
    values as DCMIPP_P1CFSCR.PIPEN
  [30] FDTFEN — Current force data type format enable
    0=Disable force data type format. The data type format used by the pipe is the one defined into DTIDx; 1=Enable force data type format. When data type DTIDA is detected by the pipe, the real pixel format considering by the pipe is the one set into the FDTF[5:0] bit field instead of the physical one received by the CSI2 host.
  [29:24] FDTF — Current force data type format
  [20:19] VC — Current flow selection mode
  [5:0] DTIDA — Current data type ID
0xF00 DCMIPP_P2CFCTCR ro — DCMIPP Pipex current flow control configuration register
  fields as DCMIPP_P1CFCTCR
0xF04 DCMIPP_P2CCRSTR ro — DCMIPP Pipex current crop window start register
  fields as DCMIPP_P1CSTSTR
0xF08 DCMIPP_P2CCRSZR ro — DCMIPP Pipex current crop window size register
  fields as DCMIPP_P1CCRSZR
0xF0C DCMIPP_P2CDCCR — DCMIPP Pipex current decimation register
  fields as DCMIPP_P1DCCR
0xF10 DCMIPP_P2CDSCR ro — DCMIPP Pipex current downsize configuration register
  fields as DCMIPP_P1CDSCR
0xF14 DCMIPP_P2CDSRTIOR ro — DCMIPP Pipex current downsize ratio register
  fields as DCMIPP_P1CDSRTIOR
0xF18 DCMIPP_P2CDSSZR ro — DCMIPP Pipex current downsize destination size register
  fields as DCMIPP_P1CDSSZR
0xF20 DCMIPP_P2CCMRICR ro — DCMIPP Pipex current common ROI configuration register
  fields as DCMIPP_P1CCMRICR
{0xF1C+8i} DCMIPP_P2CRI{i}CR1 ro (i=1..8) — DCMIPP Pipe2 current ROI{i} configuration register 1
  fields as DCMIPP_P1CRI1CR1
{0xF20+8i} DCMIPP_P2CRI{i}CR2 ro (i=1..8) — DCMIPP Pipe2 current ROI{i} configuration register 2
  fields as DCMIPP_P1CDSSZR
0xFC0 DCMIPP_P2CPPCR ro — DCMIPP Pipe2 current pixel packer configuration register
  fields as DCMIPP_P2PPCR
